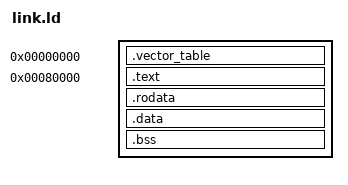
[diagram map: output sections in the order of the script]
ENTRY(start)
 
SECTIONS
{
    .vector_table 0x0 : {
        KEEP(*(.vector_table))
    }
    /* start at this address, the defaulty 64-bit kernel placement for the pi. */
    . = 0x80000;
    __start = .;
    __text_start = .;
    .text :
    {
        KEEP(*(.text.boot))
        *(.text)
    }
    . = ALIGN(4096); /* align to page size */
    __text_end = .;
 
    __rodata_start = .;
    .rodata :
    {
        *(.rodata)
        /* this is needed for rust to put .rodata..L__unnamed_1 here*/
        *(.rodata*)
    }
    . = ALIGN(4096); /* align to page size */
    __rodata_end = .;
 
    __data_start = .;
    .data :
    {
        *(.data)
    }
    . = ALIGN(4096); /* align to page size */
    __data_end = .;
 
    __bss_start = .;
    .bss :
    {
        bss = .;
        *(.bss)
    }
    . = ALIGN(4096); /* align to page size */
    __bss_end = .;
    __bss_size = __bss_end - __bss_start;
    __end = .;

    /DISCARD/ : { *(.comment) *(.gnu*) *(.note*) *(.eh_frame*) *(.ARM.exidx)}
    
}
